# ATSAMA5D21 register map
Vendor: Microchip Technology; Series: SAMA5D2; File version: 0
Registers are 32-bit, read-write, reset 0x0 unless marked. A register's access mark holds for its fields unless they carry their own. Offsets are from the block's base; [hi:lo] are bit positions; {n}, {i} and the like mark numbered series.

## ACC — Analog Comparator Controller
Base 0xF804A000
0x00 CR wo — Control Register
  [0] SWRST — Software Reset
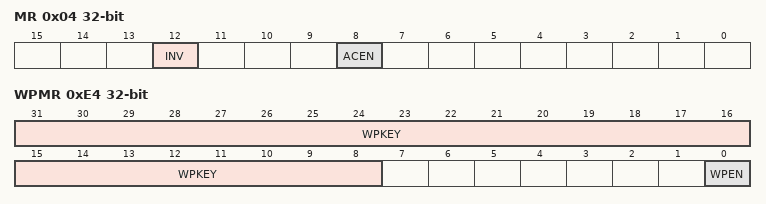
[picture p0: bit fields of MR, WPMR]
0x04 MR — Mode Register
  [12] INV — Invert Comparator Output
    0=DIS (Analog comparator output is directly processed.); 1=EN (Analog comparator output is inverted prior to being processed.)
  [8] ACEN — Analog Comparator Enable
    0=DIS (Analog comparator disabled.); 1=EN (Analog comparator enabled.)
0xE4 WPMR — Write Protection Mode Register
  [31:8] WPKEY — Write Protection Key
    0x414343=PASSWD (Writing any other value in this field aborts the write operation of the WPEN bit.Always reads as 0.)
  [0] WPEN — Write Protection Enable
0xE8 WPSR ro — Write Protection Status Register
  [0] WPVS — Write Protection Violation Status

## AIC — Advanced Interrupt Controller
Base 0xFC020000
Same registers: SAIC 0xF803C000
0x00 SSR — Source Select Register
  [6:0] INTSEL — Interrupt Line Selection
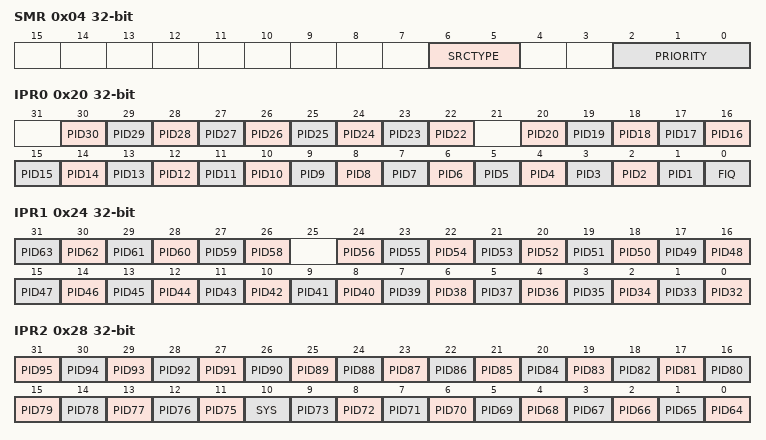
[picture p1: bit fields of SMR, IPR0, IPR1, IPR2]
0x04 SMR — Source Mode Register
  [6:5] SRCTYPE — Interrupt Source Type
    0=INT_LEVEL_SENSITIVE (High-level sensitive for internal source. Low-level sensitive for external source); 1=EXT_NEGATIVE_EDGE (Negative-edge triggered for external source); 2=EXT_HIGH_LEVEL (High-level sensitive for internal source. High-level sensitive for external source); 3=EXT_POSITIVE_EDGE (Positive-edge triggered for external source)
  [2:0] PRIORITY — Priority Level
    0=MINIMUM (Minimum priority); 1=VERY_LOW (Very low priority); 2=LOW (Low priority); 3=MEDIUM_LOW (Medium priority); 4=MEDIUM_HIGH (Medium-high priority); 5=HIGH (High priority); 6=VERY_HIGH (Very high priority); 7=MAXIMUM (Maximum priority)
0x08 SVR — Source Vector Register
  [31:0] VECTOR — Source Vector
0x10 IVR ro — Interrupt Vector Register
  [31:0] IRQV
0x14 FVR ro — FIQ Vector Register
  [31:0] FIQV
0x18 ISR ro — Interrupt Status Register
  [6:0] IRQID — Current Interrupt Identifier
0x20 IPR0 ro — Interrupt Pending Register 0
  [n] PID{n} (n=22..30) — Interrupt Pending
  [n] PID{n} (n=1..20) — Interrupt Pending
  [0] FIQ — Interrupt Pending
0x24 IPR1 ro — Interrupt Pending Register 1
  [n-32] PID{n} (n=58..63) — Interrupt Pending
  [n-32] PID{n} (n=32..56) — Interrupt Pending
0x28 IPR2 ro — Interrupt Pending Register 2
  [n-64] PID{n} (n=75..95) — Interrupt Pending
  [10] SYS — Interrupt Pending
  [n-64] PID{n} (n=64..73) — Interrupt Pending
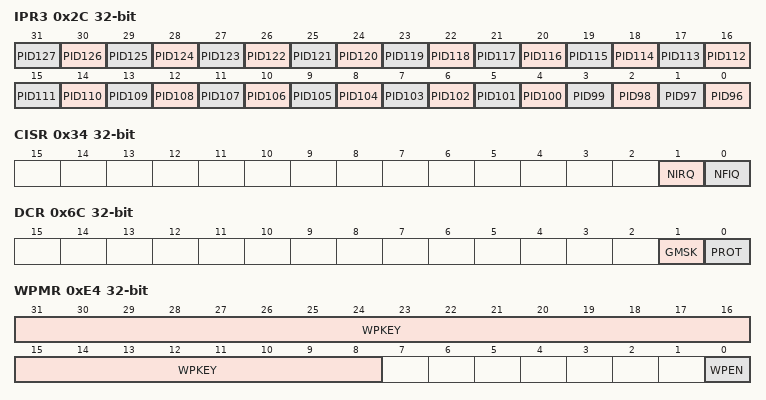
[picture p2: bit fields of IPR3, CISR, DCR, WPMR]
0x2C IPR3 ro — Interrupt Pending Register 3
  [n-96] PID{n} (n=96..127) — Interrupt Pending
0x30 IMR ro — Interrupt Mask Register
  [0] INTM — Interrupt Mask
0x34 CISR ro — Core Interrupt Status Register
  [1] NIRQ — NIRQ Status
  [0] NFIQ — NFIQ Status
0x38 EOICR wo — End of Interrupt Command Register
  [0] ENDIT — Interrupt Processing Complete Command
0x3C SPU — Spurious Interrupt Vector Register
  [31:0] SIVR
0x40 IECR wo — Interrupt Enable Command Register
  [0] INTEN — Interrupt Enable
0x44 IDCR wo — Interrupt Disable Command Register
  [0] INTD — Interrupt Disable
0x48 ICCR wo — Interrupt Clear Command Register
  [0] INTCLR — Interrupt Clear
0x4C ISCR wo — Interrupt Set Command Register
  [0] INTSET — Interrupt Set
0x6C DCR — Debug Control Register
  [1] GMSK — General Interrupt Mask
  [0] PROT — Protection Mode
0xE4 WPMR — Write Protection Mode Register
  [31:8] WPKEY — Write Protection Key
    0x414943=PASSWD (Writing any other value in this field aborts the write operation of the WPEN bit.Always reads as 0.)
  [0] WPEN — Write Protection Enable
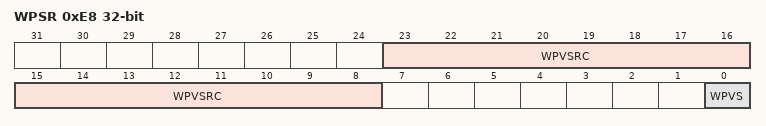
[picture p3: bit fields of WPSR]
0xE8 WPSR ro — Write Protection Status Register
  [23:8] WPVSRC — Write Protection Violation Source
  [0] WPVS — Write Protection Violation Status

## AXIMX — AXI Matrix
Base 0x00600000
0x00 REMAP wo — AXI Matrix Remap Register
  [0] REMAP0 — Remap State 0

## Notices in the file
Copyright (c) 2026 Microchip Technology Inc.
SPDX-License-Identifier: Apache-2.0
Licensed under the Apache License, Version 2.0 (the "License");
you may not use this file except in compliance with the License.
You may obtain a copy of the License at
http://www.apache.org/licenses/LICENSE-2.0
Unless required by applicable law or agreed to in writing, software
distributed under the License is distributed on an "AS IS" BASIS,
WITHOUT WARRANTIES OR CONDITIONS OF ANY KIND, either express or implied.
See the License for the specific language governing permissions and
limitations under the License.
